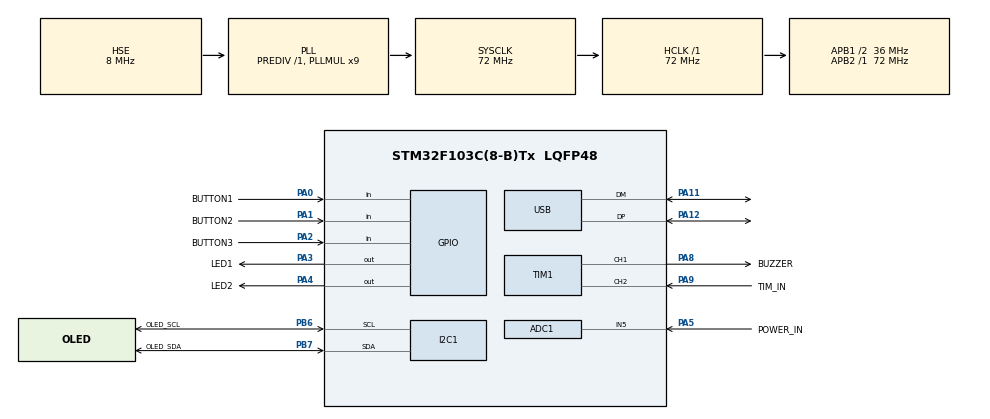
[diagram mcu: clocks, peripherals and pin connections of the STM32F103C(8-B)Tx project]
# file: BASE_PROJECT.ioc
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ADC1.Channel-0\#ChannelRegularConversion=ADC_CHANNEL_5
ADC1.ContinuousConvMode=ENABLE
ADC1.NbrOfConversionFlag=1
ADC1.Rank-0\#ChannelRegularConversion=1
ADC1.SamplingTime-0\#ChannelRegularConversion=ADC_SAMPLETIME_1CYCLE_5
ADC1.master=1
Dma.I2C1_TX.0.Direction=DMA_MEMORY_TO_PERIPH
Dma.I2C1_TX.0.Instance=DMA1_Channel6
Dma.I2C1_TX.0.MemDataAlignment=DMA_MDATAALIGN_BYTE
Dma.I2C1_TX.0.MemInc=DMA_MINC_ENABLE
Dma.I2C1_TX.0.Mode=DMA_NORMAL
Dma.I2C1_TX.0.PeriphDataAlignment=DMA_PDATAALIGN_BYTE
Dma.I2C1_TX.0.PeriphInc=DMA_PINC_DISABLE
Dma.I2C1_TX.0.Priority=DMA_PRIORITY_LOW
Dma.Request0=I2C1_TX
FREERTOS.Tasks01=defaultTask,24,128,StartDefaultTask,Default,NULL,Dynamic,NULL,NULL
Mcu.Family=STM32F1
Mcu.Name=STM32F103C(8-B)Tx
Mcu.Package=LQFP48
NVIC.DMA1_Channel6_IRQn=true\:5\:0\:false\:false\:true\:true\:false\:true\:true
NVIC.PriorityGroup=NVIC_PRIORITYGROUP_4
NVIC.TIM1_CC_IRQn=true\:5\:0\:false\:false\:true\:true\:true\:true\:true
NVIC.TIM1_UP_IRQn=true\:5\:0\:false\:false\:true\:true\:true\:true\:true
NVIC.USB_LP_CAN1_RX0_IRQn=true\:5\:0\:false\:false\:true\:true\:false\:true\:true
PA0-WKUP.GPIO_Label=BUTTON1
PA0-WKUP.GPIO_PuPd=GPIO_PULLDOWN
PA0-WKUP.Signal=GPIO_Input
PA1.GPIO_Label=BUTTON2
PA1.GPIO_PuPd=GPIO_PULLDOWN
PA1.Signal=GPIO_Input
PA11.Mode=Device
PA11.Signal=USB_DM
PA12.Mode=Device
PA12.Signal=USB_DP
PA13.Mode=Serial_Wire
PA13.Signal=SYS_JTMS-SWDIO
PA14.Mode=Serial_Wire
PA14.Signal=SYS_JTCK-SWCLK
PA2.GPIO_Label=BUTTON3
PA2.GPIO_PuPd=GPIO_PULLDOWN
PA2.Signal=GPIO_Input
PA3.GPIO_Label=LED1
PA3.Signal=GPIO_Output
PA4.GPIO_Label=LED2
PA4.Signal=GPIO_Output
PA5.GPIO_Label=POWER_IN
PA5.Signal=ADCx_IN5
PA8.GPIO_Label=BUZZER
PA8.Signal=S_TIM1_CH1
PA9.GPIO_Label=TIM_IN
PA9.Signal=S_TIM1_CH2
PB6.GPIO_Label=OLED_SCL
PB6.Mode=I2C
PB6.Signal=I2C1_SCL
PB7.GPIO_Label=OLED_SDA
PB7.Mode=I2C
PB7.Signal=I2C1_SDA
PD0-OSC_IN.Mode=HSE-External-Oscillator
PD0-OSC_IN.Signal=RCC_OSC_IN
PD1-OSC_OUT.Mode=HSE-External-Oscillator
PD1-OSC_OUT.Signal=RCC_OSC_OUT
ProjectManager.HeapSize=0x200
ProjectManager.StackSize=0x400
ProjectManager.TargetToolchain=CMake
RCC.ADCPresc=RCC_ADCPCLK2_DIV6
RCC.AHBFreq_Value=72000000
RCC.APB1CLKDivider=RCC_HCLK_DIV2
RCC.APB1Freq_Value=36000000
RCC.APB1TimFreq_Value=72000000
RCC.APB2Freq_Value=72000000
RCC.APB2TimFreq_Value=72000000
RCC.HCLKFreq_Value=72000000
RCC.PLLMUL=RCC_PLL_MUL9
RCC.SYSCLKFreq_VALUE=72000000
RCC.SYSCLKSource=RCC_SYSCLKSOURCE_PLLCLK
RCC.USBFreq_Value=48000000
RCC.USBPrescaler=RCC_USBCLKSOURCE_PLL_DIV1_5
SH.ADCx_IN5.0=ADC1_IN5,IN5
SH.S_TIM1_CH1.0=TIM1_CH1,PWM Generation1 CH1
SH.S_TIM1_CH2.0=TIM1_CH2,Input_Capture2_from_TI2
TIM1.AutoReloadPreload=TIM_AUTORELOAD_PRELOAD_DISABLE
TIM1.Channel-Input_Capture2_from_TI2=TIM_CHANNEL_2
TIM1.Channel-PWM\ Generation1\ CH1=TIM_CHANNEL_1
USB_DEVICE.CLASS_NAME_FS=CDC
USB_DEVICE.VirtualMode=Cdc
USB_DEVICE.VirtualModeFS=Cdc_FS
VP_FREERTOS_VS_CMSIS_V2.Mode=CMSIS_V2
VP_USB_DEVICE_VS_USB_DEVICE_CDC_FS.Mode=CDC_FS
board=custom

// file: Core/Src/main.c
/* USER CODE BEGIN Header */
/**
  ******************************************************************************
  * @file           : main.c
  * @brief          : Main program body
  ******************************************************************************
  * @attention
  *
  * Copyright (c) 2026 STMicroelectronics.
  * All rights reserved.
  *
  * This software is licensed under terms that can be found in the LICENSE file
  * in the root directory of this software component.
  * If no LICENSE file comes with this software, it is provided AS-IS.
  *
  ******************************************************************************
  */
/* USER CODE END Header */
#include "main.h"
#include "cmsis_os.h"
#include "adc.h"
#include "dma.h"
#include "i2c.h"
#include "tim.h"
#include "usb_device.h"
#include "gpio.h"

void SystemClock_Config(void);
void MX_FREERTOS_Init(void);

int main(void)
{

  /* MCU Configuration--------------------------------------------------------*/

  /* Reset of all peripherals, Initializes the Flash interface and the Systick. */
  HAL_Init();

  /* Configure the system clock */
  SystemClock_Config();

  /* Initialize all configured peripherals */
  MX_GPIO_Init();
  MX_DMA_Init();
  MX_I2C1_Init();
  MX_ADC1_Init();
  MX_TIM1_Init();

  /* Init scheduler */
  osKernelInitialize();  /* Call init function for freertos objects (in cmsis_os2.c) */
  MX_FREERTOS_Init();

  /* Start scheduler */
  osKernelStart();

  /* We should never get here as control is now taken by the scheduler */

  /* Infinite loop */
  while (1)
  {

  }
}

void SystemClock_Config(void)
{
  RCC_OscInitTypeDef RCC_OscInitStruct = {0};
  RCC_ClkInitTypeDef RCC_ClkInitStruct = {0};
  RCC_PeriphCLKInitTypeDef PeriphClkInit = {0};

  /** Initializes the RCC Oscillators according to the specified parameters
  * in the RCC_OscInitTypeDef structure.
  */
  RCC_OscInitStruct.OscillatorType = RCC_OSCILLATORTYPE_HSE;
  RCC_OscInitStruct.HSEState = RCC_HSE_ON;
  RCC_OscInitStruct.HSEPredivValue = RCC_HSE_PREDIV_DIV1;
  RCC_OscInitStruct.HSIState = RCC_HSI_ON;
  RCC_OscInitStruct.PLL.PLLState = RCC_PLL_ON;
  RCC_OscInitStruct.PLL.PLLSource = RCC_PLLSOURCE_HSE;
  RCC_OscInitStruct.PLL.PLLMUL = RCC_PLL_MUL9;
  if (HAL_RCC_OscConfig(&RCC_OscInitStruct) != HAL_OK)
  {
    Error_Handler();
  }

  /** Initializes the CPU, AHB and APB buses clocks
  */
  RCC_ClkInitStruct.ClockType = RCC_CLOCKTYPE_HCLK|RCC_CLOCKTYPE_SYSCLK
                              |RCC_CLOCKTYPE_PCLK1|RCC_CLOCKTYPE_PCLK2;
  RCC_ClkInitStruct.SYSCLKSource = RCC_SYSCLKSOURCE_PLLCLK;
  RCC_ClkInitStruct.AHBCLKDivider = RCC_SYSCLK_DIV1;
  RCC_ClkInitStruct.APB1CLKDivider = RCC_HCLK_DIV2;
  RCC_ClkInitStruct.APB2CLKDivider = RCC_HCLK_DIV1;

  if (HAL_RCC_ClockConfig(&RCC_ClkInitStruct, FLASH_LATENCY_2) != HAL_OK)
  {
    Error_Handler();
  }
  PeriphClkInit.PeriphClockSelection = RCC_PERIPHCLK_ADC|RCC_PERIPHCLK_USB;
  PeriphClkInit.AdcClockSelection = RCC_ADCPCLK2_DIV6;
  PeriphClkInit.UsbClockSelection = RCC_USBCLKSOURCE_PLL_DIV1_5;
  if (HAL_RCCEx_PeriphCLKConfig(&PeriphClkInit) != HAL_OK)
  {
    Error_Handler();
  }
}

void Error_Handler(void)
{
  __disable_irq();
  while (1)
  {
  }
}

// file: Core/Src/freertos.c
/* USER CODE BEGIN Header */
/**
  ******************************************************************************
  * File Name          : freertos.c
  * Description        : Code for freertos applications
  ******************************************************************************
  * @attention
  *
  * Copyright (c) 2026 STMicroelectronics.
  * All rights reserved.
  *
  * This software is licensed under terms that can be found in the LICENSE file
  * in the root directory of this software component.
  * If no LICENSE file comes with this software, it is provided AS-IS.
  *
  ******************************************************************************
  */
/* USER CODE END Header */

#include "FreeRTOS.h"
#include "task.h"
#include "main.h"
#include "cmsis_os.h"

/* USER CODE BEGIN Includes */
#include "user_main.h"
/* USER CODE END Includes */

/* Definitions for defaultTask */
osThreadId_t defaultTaskHandle;
const osThreadAttr_t defaultTask_attributes = {
  .name = "defaultTask",
  .stack_size = 128 * 4,
  .priority = (osPriority_t) osPriorityNormal,
};

void StartDefaultTask(void *argument);

extern void MX_USB_DEVICE_Init(void);
void MX_FREERTOS_Init(void); /* (MISRA C 2004 rule 8.1) */

void MX_FREERTOS_Init(void) {

  /* Create the thread(s) */
  /* creation of defaultTask */
  defaultTaskHandle = osThreadNew(StartDefaultTask, NULL, &defaultTask_attributes);

}

void StartDefaultTask(void *argument)
{
  /* init code for USB_DEVICE */
  MX_USB_DEVICE_Init();
  /* USER CODE BEGIN StartDefaultTask */
  user_main();   /* 创建按键/LED/ADC/蜂鸣器/捕获/CDC/OLED 任务 */
  /* Infinite loop */
  for(;;)
  {
    osDelay(1000);
  }
  /* USER CODE END StartDefaultTask */
}
